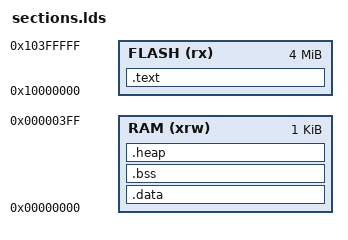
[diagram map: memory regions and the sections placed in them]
/*
# SPDX-FileCopyrightText: 2020 Efabless Corporation
#
# Licensed under the Apache License, Version 2.0 (the "License");
# you may not use this file except in compliance with the License.
# You may obtain a copy of the License at
#
#     http://www.apache.org/licenses/LICENSE-2.0
#
# Unless required by applicable law or agreed to in writing, software
# distributed under the License is distributed on an "AS IS" BASIS,
# WITHOUT WARRANTIES OR CONDITIONS OF ANY KIND, either express or implied.
# See the License for the specific language governing permissions and
# limitations under the License.
# SPDX-License-Identifier: Apache-2.0
*/

ENTRY(_start)

MEMORY {
    FLASH (rx)  : ORIGIN = 0x10000000, LENGTH = 0x400000
    RAM   (xrw) : ORIGIN = 0x00000000, LENGTH = 0x0400
}

SECTIONS {
    .text :
    {
        . = ALIGN(4);
        KEEP(*(.init))
        KEEP(*(.text))
        KEEP(*(.text*))
        *(.rodata)
        *(.rodata*)
        *(.srodata)
        *(.srodata*)
        . = ALIGN(4);
        _etext   = .;
        _sidata  = _etext;
    } >FLASH

    .data : AT ( _sidata )
    {
        . = ALIGN(4);
        _sdata     = .;
        _ram_start = .;
        . = ALIGN(4);
        *(.data)
        *(.data*)
        *(.sdata)
        *(.sdata*)
        . = ALIGN(4);
        _edata = .;
    } >RAM

    .bss :
    {
        . = ALIGN(4);
        _sbss = .;
        *(.bss)
        *(.bss*)
        *(.sbss)
        *(.sbss*)
        *(COMMON)
        . = ALIGN(4);
        _ebss = .;
    } >RAM

    .heap :
    {
        . = ALIGN(4);
        _heap_start = .;
    } >RAM
}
